# cameraif_reva_ai85 register map
Registers are 32-bit, read-write, no defined reset value unless marked. A register's access mark holds for its fields unless they carry their own. Offsets are from the block's base; lines under a group give offsets from that group; [hi:lo] are bit positions; {n}, {i} and the like mark numbered series; 'fields as' and 'values as' point back to an identical list; <NAME> marks a mode.

## Memory map
0x4000E000 CAMERAIF size 0x1000 — Parallel Camera Interface.

## Interrupts
91 CameraIF (CAMERAIF)

## CAMERAIF — Parallel Camera Interface.
Base 0x4000E000
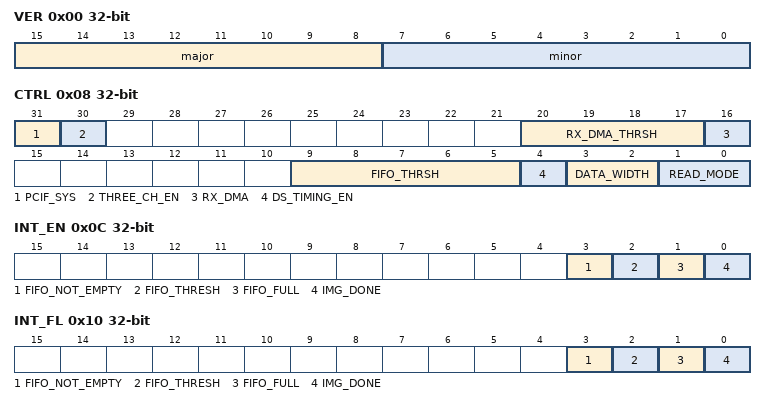
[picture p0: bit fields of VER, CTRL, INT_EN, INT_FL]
0x00 VER — Hardware Version.
  [15:8] major — Major Version Number.
  [7:0] minor — Minor Version Number.
0x04 FIFO_SIZE — FIFO Depth.
  [7:0] fifo_size
0x08 CTRL — Control Register.
  [31] PCIF_SYS — PCIF Control.
    0=dis (PCIF disabled.); 1=en (PCIF enabled.)
  [30] THREE_CH_EN — Three-channel mode enable.
  [20:17] RX_DMA_THRSH — DMA Threshold.
  [16] RX_DMA — DMA Enable.
    0=dis (DMA disabled.); 1=en (DMA enabled.)
  [9:5] FIFO_THRSH — Data FIFO Threshold.
  [4] DS_TIMING_EN — DS Timing Enable.
    0=dis (Timing from VSYNC and HSYNC.); 1=en (Timing embedded in data using SAV and EAV codes.)
  [3:2] DATA_WIDTH
    0=8bit; 1=10bit; 2=12bit
  [1:0] READ_MODE
    0=dis (Camera Interface Disabled.); 1=single_img (Single Image Capture.); 2=Continuous Image Capture
0x0C INT_EN — Interrupt Enable Register.
  [3] FIFO_NOT_EMPTY
  [2] FIFO_THRESH — FIFO Threshold Level Met.
  [1] FIFO_FULL
  [0] IMG_DONE — Image Done.
0x10 INT_FL — Interrupt Flag Register.
  fields as INT_EN
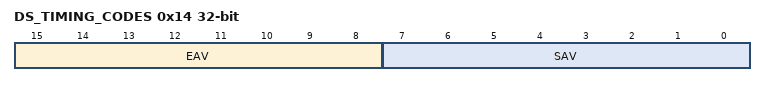
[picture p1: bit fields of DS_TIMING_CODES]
0x14 DS_TIMING_CODES — DS Timing Code Register.
  [15:8] EAV — End Active Video Code.
  [7:0] SAV — Start Active Video Code.
0x30 FIFO_DATA
  [31:0] DATA — Data from FIFO to be read by DMA.
